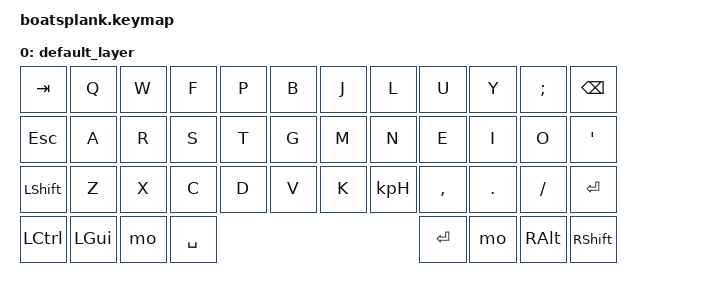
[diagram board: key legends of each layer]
#include <behaviors.dtsi>
#include <dt-bindings/zmk/keys.h>
#include <dt-bindings/zmk/bt.h>

/ {
  keymap {
    compatible = "zmk,keymap";

    default_layer {
      bindings = <
        &kp TAB       &kp Q     &kp W   &kp F     &kp P   &kp B     &kp J     &kp L     &kp U     &kp Y     &kp SEMI  &kp BSPC
        &kp ESC       &kp A     &kp R   &kp S     &kp T   &kp G     &kp M     &kp N     &kp E     &kp I     &kp O     &kp SQT
        &kp LSHFT     &kp Z     &kp X   &kp C     &kp D   &kp V     &kp K     &kp KP_H  &kp COMMA &kp DOT   &kp SLASH &kp RET
        &kp LCTRL     &kp LGUI          &kp mo 1          &kp SPACE &kp RET           &kp mo 2            &kp RALT    &kp RSHFT


      >;
    };
  }
}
